AUTOSAR XML (schema 321)
package /ComponentType
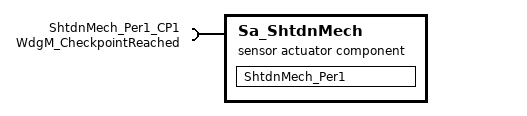
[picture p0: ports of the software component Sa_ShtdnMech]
  sensor actuator software component type Sa_ShtdnMech
    require port ShtdnMech_Per1_CP1: client-com-spec=CheckpointReached, required-interface=WdgM_CheckpointReached
  internal behavior Sa_ShtdnMech_InternalBehavior: component=Sa_ShtdnMech, port-api-option{enable-take-address=false, indirect-api=false, port=ShtdnMech_Per1_CP1}
    runnable ShtdnMech_Per1
      sync call SC_ShtdnMech_Per1_CP1_CheckpointReached: operation=ShtdnMech_Per1_CP1.CheckpointReached, timeout=0
  swc implementation Sa_ShtdnMech_Implementation: behavior=Sa_ShtdnMech_InternalBehavior
    code-descriptors:
      code Code: type=SRC
package /PortInterface
  client server interface WdgM_CheckpointReached: is-service=true
    operation CheckpointReached: possible-error=E_NOT_OK  # Indicates to the Watchdog Manager that a Checkpoint within a Supervised Entity has been reached.
    error E_NOT_OK: error-code=1
